# PY32F403xx register map
Vendor: PUYA Co.Ltd; Series: ARMCM4; File version: 1.2
CPU: CM4 r0p1, little endian, MPU, FPU, 4 interrupt priority bits
Registers are 32-bit, read-write, reset 0x0 unless marked. A register's access mark holds for its fields unless they carry their own. Offsets are from the block's base; [hi:lo] are bit positions; {n}, {i} and the like mark numbered series.

## ADC1 — desc ADC
Base 0x40012400
Same registers: ADC2 0x40012800, ADC3 0x40013C00
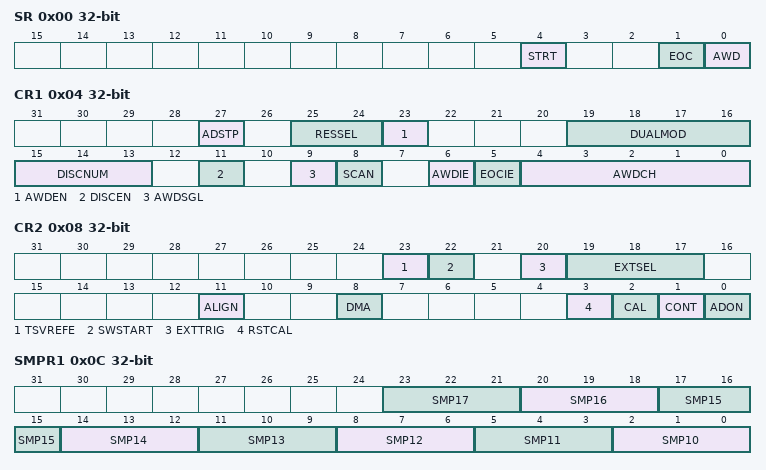
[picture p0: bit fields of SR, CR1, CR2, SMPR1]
0x00 SR
  [4] STRT, [1] EOC, [0] AWD
0x04 CR1
  [27] ADSTP
  [25:24] RESSEL
    1=0; 2=1
  [23] AWDEN
  [19:16] DUALMOD
    1=0; 2=1; 4=2; 8=3
  [15:13] DISCNUM
    1=0; 2=1; 4=2
  [11] DISCEN
  [9] AWDSGL
  [8] SCAN
  [6] AWDIE
  [5] EOCIE
  [4:0] AWDCH
    1=0; 2=1; 4=2; 8=3; 16=4
0x08 CR2
  [23] TSVREFE
  [22] SWSTART
  [20] EXTTRIG
  [19:17] EXTSEL
    1=0; 2=1; 4=2
  [11] ALIGN
  [8] DMA
  [3] RSTCAL
  [2] CAL
  [1] CONT
  [0] ADON
0x0C SMPR1
  [all] fields
    1=0; 2=1; 4=2
  [3n-28:3n-30] SMP{n} (n=10..17)
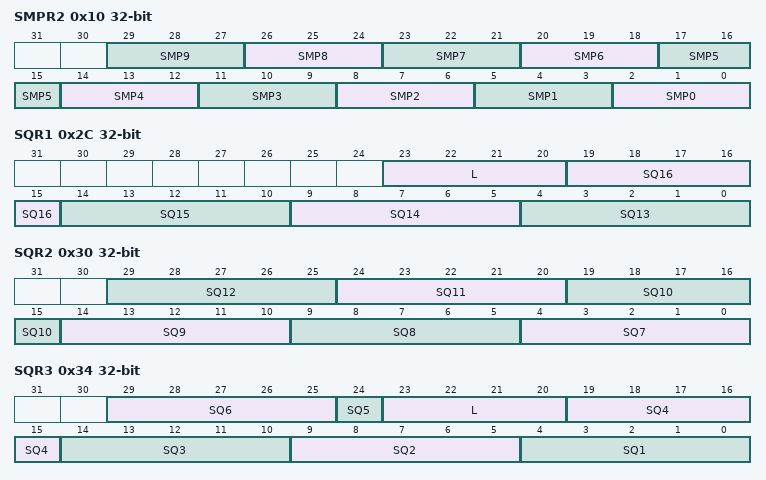
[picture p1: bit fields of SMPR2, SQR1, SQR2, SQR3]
0x10 SMPR2
  [all] fields
    1=0; 2=1; 4=2
  [3n+2:3n] SMP{n} (n=0..9)
0x24 HTR
  [11:0] HT
0x28 LTR
  [11:0] LT
0x2C SQR1
  [23:20] L
    1=0; 2=1; 4=2; 8=3
  [5n-61:5n-65] SQ{n} (n=13..16)
    1=0; 2=1; 4=2; 8=3; 16=4
0x30 SQR2
  [all] fields
    1=0; 2=1; 4=2; 8=3; 16=4
  [5n-31:5n-35] SQ{n} (n=7..12)
0x34 SQR3
  [29:25] SQ6
    1=0; 2=1; 4=2; 8=3; 16=4
  [24] SQ5
  [23:20] L
  [5n-1:5n-5] SQ{n} (n=1..4)
    1=0; 2=1; 4=2; 8=3; 16=4
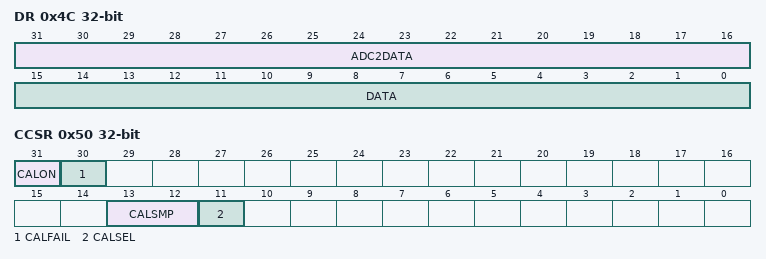
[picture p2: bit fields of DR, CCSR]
0x4C DR
  [31:16] ADC2DATA ro, [15:0] DATA ro
0x50 CCSR
  [31] CALON ro
  [30] CALFAIL
  [13:12] CALSMP
    1=0; 2=1
  [11] CALSEL

## BKP
Base 0x40006C00
{0x0+4i} DR{i} (i=1..10)
  [15:0] D
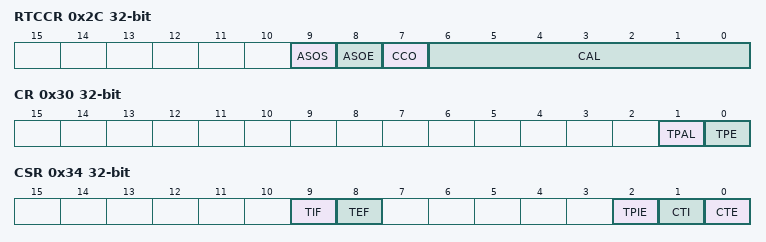
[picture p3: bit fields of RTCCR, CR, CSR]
0x2C RTCCR
  [9] ASOS
  [8] ASOE
  [7] CCO
  [6:0] CAL
    1=0; 2=1; 4=2; 8=3; 16=4; 32=5; 64=6
0x30 CR
  [1] TPAL, [0] TPE
0x34 CSR
  [9] TIF ro, [8] TEF ro, [2] TPIE, [1] CTI, [0] CTE
{0x14+4i} DR{i} (i=11..42)
  [15:0] D

## CANFD
Base 0x40008000
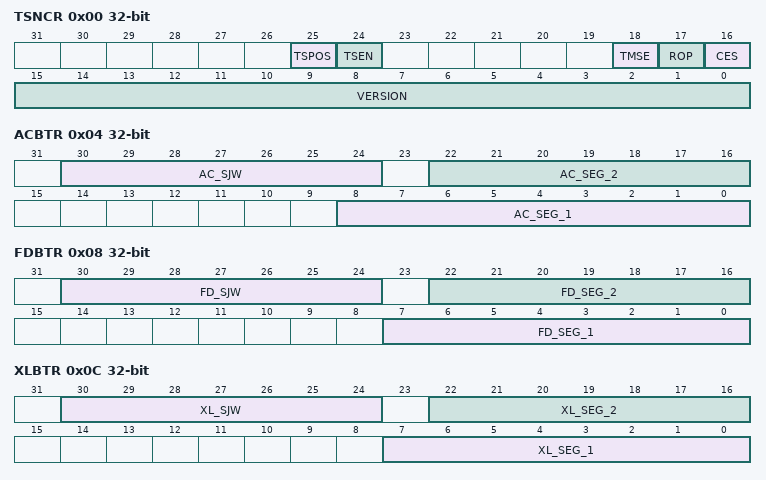
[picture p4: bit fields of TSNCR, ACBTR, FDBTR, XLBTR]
0x00 TSNCR
  [25] TSPOS, [24] TSEN, [18] TMSE, [17] ROP, [16] CES, [15:0] VERSION ro
0x04 ACBTR
  [30:24] AC_SJW
    1=0; 2=1; 4=2; 8=3; 16=4; 32=5; 64=6
  [22:16] AC_SEG_2
    1=0; 2=1; 4=2; 8=3; 16=4; 32=5; 64=6
  [8:0] AC_SEG_1
0x08 FDBTR
  [30:24] FD_SJW
    1=0; 2=1; 4=2; 8=3; 16=4; 32=5; 64=6
  [22:16] FD_SEG_2
    1=0; 2=1; 4=2; 8=3; 16=4; 32=5; 64=6
  [7:0] FD_SEG_1
0x0C XLBTR
  [30:24] XL_SJW, [22:16] XL_SEG_2, [7:0] XL_SEG_1
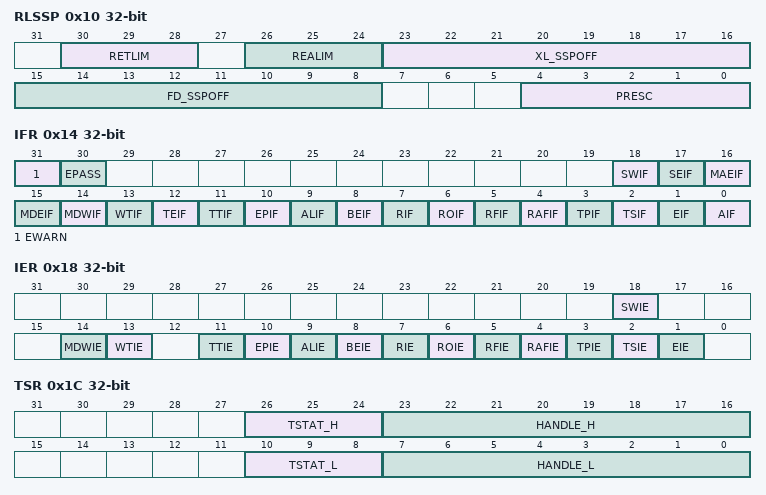
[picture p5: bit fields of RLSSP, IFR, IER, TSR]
0x10 RLSSP
  [30:28] RETLIM
    1=0; 2=1; 4=2
  [26:24] REALIM
    1=0; 2=1; 4=2
  [23:16] XL_SSPOFF
  [15:8] FD_SSPOFF
  [4:0] PRESC
    1=0; 2=1; 4=2; 8=3; 16=4
0x14 IFR
  [31] EWARN ro, [30] EPASS ro, [18] SWIF, [17] SEIF, [16] MAEIF, [15] MDEIF, [14] MDWIF, [13] WTIF, [12] TEIF, [11] TTIF, [10] EPIF, [9] ALIF, [8] BEIF, [7] RIF, [6] ROIF, [5] RFIF, [4] RAFIF, [3] TPIF, [2] TSIF, [1] EIF, [0] AIF
0x18 IER
  [18] SWIE, [14] MDWIE, [13] WTIE, [11] TTIE, [10] EPIE, [9] ALIE, [8] BEIE, [7] RIE, [6] ROIE, [5] RFIE, [4] RAFIE, [3] TPIE, [2] TSIE, [1] EIE
0x1C TSR
  [26:24] TSTAT_H ro
    1=0; 2=1; 4=2
  [23:16] HANDLE_H ro
  [10:8] TSTAT_L ro
    1=0; 2=1; 4=2
  [7:0] HANDLE_L ro
0x20 TTSL
  [31:0] TTS ro
0x24 TTSH
  [31:0] TTS ro
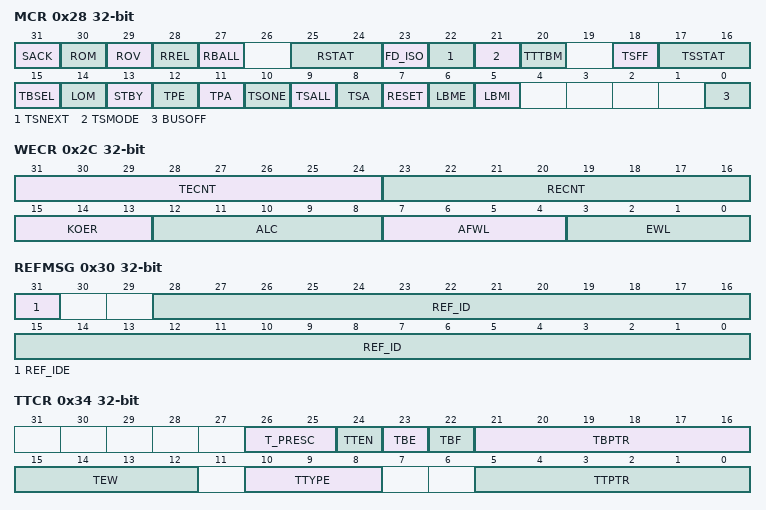
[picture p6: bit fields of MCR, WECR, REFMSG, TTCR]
0x28 MCR
  [31] SACK
  [30] ROM
  [29] ROV ro
  [28] RREL
  [27] RBALL
  [25:24] RSTAT ro
    1=0; 2=1
  [23] FD_ISO
  [22] TSNEXT
  [21] TSMODE
  [20] TTTBM
  [18] TSFF ro
  [17:16] TSSTAT ro
    1=0; 2=1
  [15] TBSEL
  [14] LOM
  [13] STBY
  [12] TPE
  [11] TPA
  [10] TSONE
  [9] TSALL
  [8] TSA
  [7] RESET
  [6] LBME
  [5] LBMI
  [0] BUSOFF
0x2C WECR
  [31:24] TECNT ro
  [23:16] RECNT ro
  [15:13] KOER ro
    1=0; 2=1; 4=2
  [12:8] ALC ro
    1=0; 2=1; 4=2; 8=3; 16=4
  [7:4] AFWL
    1=0; 2=1; 4=2; 8=3
  [3:0] EWL
    1=0; 2=1; 4=2; 8=3
0x30 REFMSG
  [31] REF_IDE, [28:0] REF_ID
0x34 TTCR
  [26:25] T_PRESC
    1=0; 2=1
  [24] TTEN
  [23] TBE
  [22] TBF
  [21:16] TBPTR
    1=0; 2=1; 4=2; 8=3; 16=4; 32=5
  [15:12] TEW
    1=0; 2=1; 4=2; 8=3
  [10:8] TTYPE
    1=0; 2=1; 4=2
  [5:0] TTPTR
    1=0; 2=1; 4=2; 8=3; 16=4; 32=5
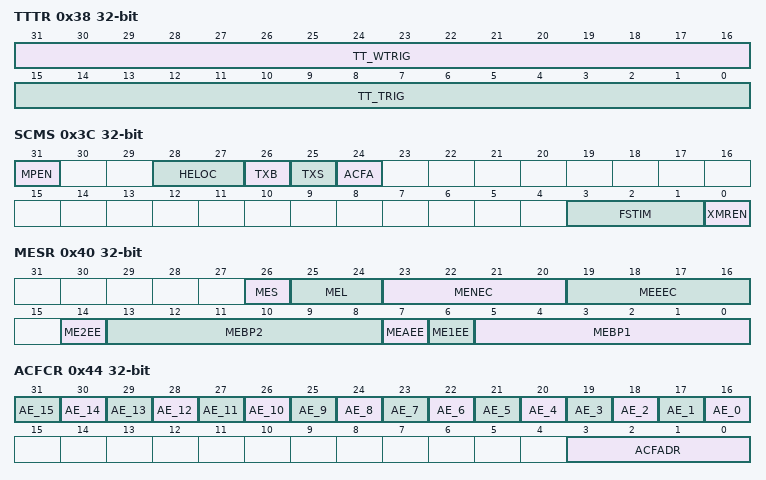
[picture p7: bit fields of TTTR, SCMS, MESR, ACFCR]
0x38 TTTR
  [31:16] TT_WTRIG, [15:0] TT_TRIG
0x3C SCMS
  [31] MPEN
  [28:27] HELOC ro
    1=0; 2=1
  [26] TXB ro
  [25] TXS ro
  [24] ACFA
  [3:1] FSTIM
    1=0; 2=1; 4=2
  [0] XMREN
0x40 MESR
  [26] MES, [25:24] MEL, [23:20] MENEC, [19:16] MEEEC, [14] ME2EE, [13:8] MEBP2, [7] MEAEE, [6] ME1EE, [5:0] MEBP1
0x44 ACFCR
  [n+16] AE_{n} (n=0..15)
  [3:0] ACFADR
    1=0; 2=1; 4=2; 8=3
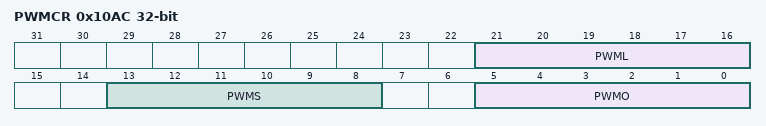
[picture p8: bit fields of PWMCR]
0x10AC PWMCR
  [21:16] PWML, [13:8] PWMS, [5:0] PWMO
